VERSION ""

NS_ :

BS_:

BU_: BMC ODESC

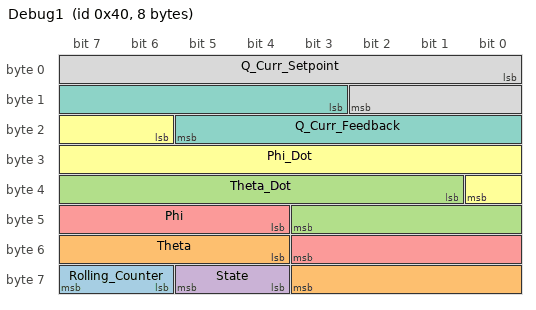
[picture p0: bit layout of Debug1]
BO_ 64 Debug1: 8 ODESC
 SG_ Rolling_Counter : 62|2@1+ (1,0) [0|3] "" Vector__XXX
 SG_ Theta : 52|8@1+ (0.025,0) [0|6.375] "" Vector__XXX
 SG_ Theta_Dot : 33|11@1+ (0.1,-102.4) [-102.4|102.3] "" Vector__XXX
 SG_ State : 60|2@1+ (1,0) [0|3] "" Vector__XXX
 SG_ Phi : 44|8@1+ (0.025,-3.2) [-3.2|3.175] "" Vector__XXX
 SG_ Phi_Dot : 22|11@1+ (0.1,-102.4) [-102.4|102.3] "" Vector__XXX
 SG_ Q_Curr_Feedback : 11|11@1+ (0.001,-1.024) [-1.024|1.023] "" Vector__XXX
 SG_ Q_Curr_Setpoint : 0|11@1+ (0.001,-1.024) [-1.024|1.023] "" Vector__XXX

BA_DEF_  "BusType" STRING ;
BA_DEF_DEF_  "BusType" "CAN";
